# ioADuCM4050 register map
Registers are 16-bit, access not given, no defined reset value unless marked. A register's access mark holds for its fields unless they carry their own. Addresses are absolute; registers are grouped by the start of their names; [hi:lo] are bit positions; {n}, {i} and the like mark numbered series.

## UART1
0x40005400 UART1_RX
  [7:0] RBR
0x40005400 UART1_TX
  [7:0] THR
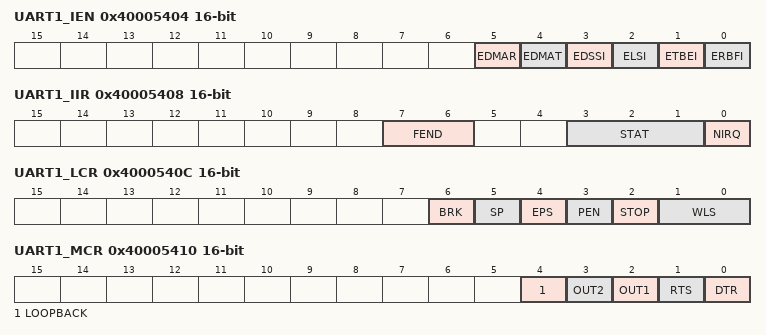
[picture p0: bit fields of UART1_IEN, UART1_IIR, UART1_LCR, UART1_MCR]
0x40005404 UART1_IEN
  [5] EDMAR, [4] EDMAT, [3] EDSSI, [2] ELSI, [1] ETBEI, [0] ERBFI
0x40005408 UART1_IIR
  [7:6] FEND, [3:1] STAT, [0] NIRQ
0x4000540C UART1_LCR
  [6] BRK, [5] SP, [4] EPS, [3] PEN, [2] STOP, [1:0] WLS
0x40005410 UART1_MCR
  [4] LOOPBACK, [3] OUT2, [2] OUT1, [1] RTS, [0] DTR
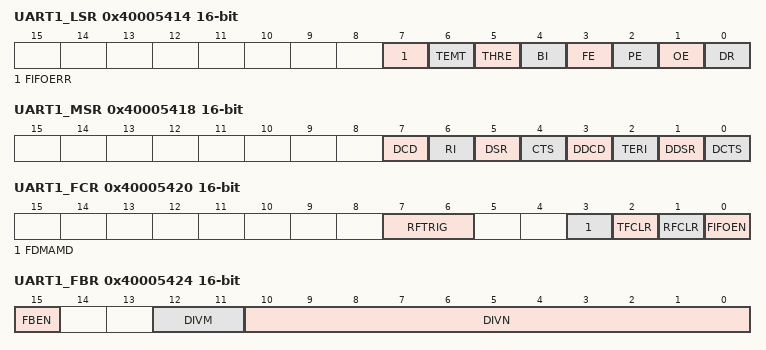
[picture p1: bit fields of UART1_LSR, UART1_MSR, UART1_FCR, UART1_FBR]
0x40005414 UART1_LSR
  [7] FIFOERR, [6] TEMT, [5] THRE, [4] BI, [3] FE, [2] PE, [1] OE, [0] DR
0x40005418 UART1_MSR
  [7] DCD, [6] RI, [5] DSR, [4] CTS, [3] DDCD, [2] TERI, [1] DDSR, [0] DCTS
0x4000541C UART1_SCR
  [7:0] SCR
0x40005420 UART1_FCR
  [7:6] RFTRIG, [3] FDMAMD, [2] TFCLR, [1] RFCLR, [0] FIFOEN
0x40005424 UART1_FBR
  [15] FBEN, [12:11] DIVM, [10:0] DIVN
0x40005428 UART1_DIV
0x4000542C UART1_LCR2
  [1:0] OSR
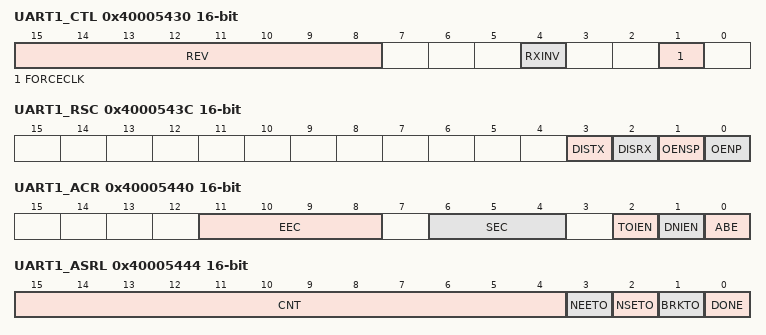
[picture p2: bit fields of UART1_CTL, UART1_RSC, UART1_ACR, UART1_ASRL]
0x40005430 UART1_CTL
  [15:8] REV, [4] RXINV, [1] FORCECLK
0x40005434 UART1_RFC
  [4:0] RFC
0x40005438 UART1_TFC
  [4:0] TFC
0x4000543C UART1_RSC
  [3] DISTX, [2] DISRX, [1] OENSP, [0] OENP
0x40005440 UART1_ACR
  [11:8] EEC, [6:4] SEC, [2] TOIEN, [1] DNIEN, [0] ABE
0x40005444 UART1_ASRL
  [15:4] CNT, [3] NEETO, [2] NSETO, [1] BRKTO, [0] DONE
0x40005448 UART1_ASRH
  [7:0] CNT

## BEEP0
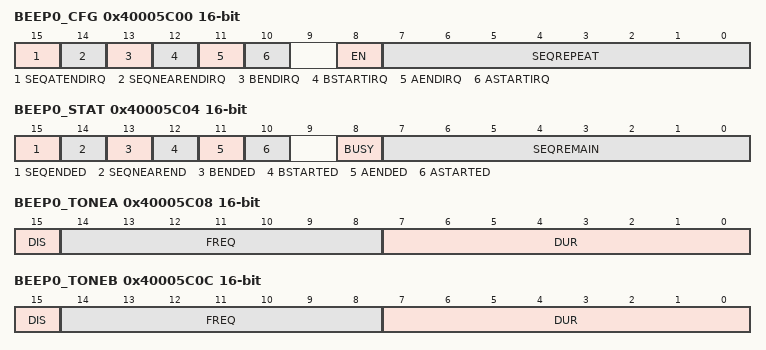
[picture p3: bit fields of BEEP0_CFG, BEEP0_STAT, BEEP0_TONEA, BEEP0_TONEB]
0x40005C00 BEEP0_CFG
  [15] SEQATENDIRQ, [14] SEQNEARENDIRQ, [13] BENDIRQ, [12] BSTARTIRQ, [11] AENDIRQ, [10] ASTARTIRQ, [8] EN, [7:0] SEQREPEAT
0x40005C04 BEEP0_STAT
  [15] SEQENDED, [14] SEQNEAREND, [13] BENDED, [12] BSTARTED, [11] AENDED, [10] ASTARTED, [8] BUSY, [7:0] SEQREMAIN
0x40005C08 BEEP0_TONEA
  [15] DIS, [14:8] FREQ, [7:0] DUR
0x40005C0C BEEP0_TONEB
  [15] DIS, [14:8] FREQ, [7:0] DUR

## ADC0
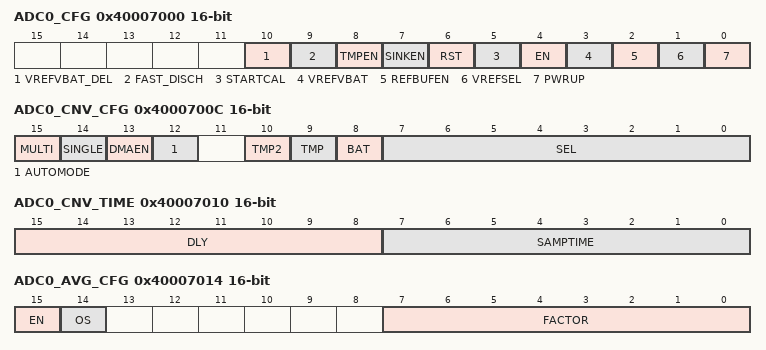
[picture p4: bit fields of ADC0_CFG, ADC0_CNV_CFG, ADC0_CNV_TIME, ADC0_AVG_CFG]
0x40007000 ADC0_CFG
  [10] VREFVBAT_DEL, [9] FAST_DISCH, [8] TMPEN, [7] SINKEN, [6] RST, [5] STARTCAL, [4] EN, [3] VREFVBAT, [2] REFBUFEN, [1] VREFSEL, [0] PWRUP
0x40007004 ADC0_PWRUP
  [10:0] WAIT
0x40007008 ADC0_CAL_WORD
  [6:0] VALUE
0x4000700C ADC0_CNV_CFG
  [15] MULTI, [14] SINGLE, [13] DMAEN, [12] AUTOMODE, [10] TMP2, [9] TMP, [8] BAT, [7:0] SEL
0x40007010 ADC0_CNV_TIME
  [15:8] DLY, [7:0] SAMPTIME
0x40007014 ADC0_AVG_CFG
  [15] EN, [14] OS, [7:0] FACTOR
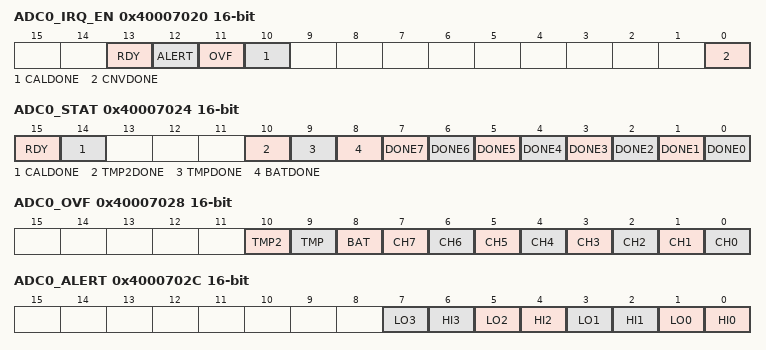
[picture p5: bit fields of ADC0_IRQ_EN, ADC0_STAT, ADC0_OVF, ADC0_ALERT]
0x40007020 ADC0_IRQ_EN
  [13] RDY, [12] ALERT, [11] OVF, [10] CALDONE, [0] CNVDONE
0x40007024 ADC0_STAT
  [15] RDY, [14] CALDONE, [10] TMP2DONE, [9] TMPDONE, [8] BATDONE, [n] DONE{n} (n=0..7)
0x40007028 ADC0_OVF
  [10] TMP2, [9] TMP, [8] BAT, [n] CH{n} (n=0..7)
0x4000702C ADC0_ALERT
  [2n+1] LO{n} (n=0..3), [2n] HI{n} (n=0..3)
{0x40007030+4i} ADC0_CH{i}_OUT (i=0..7)
0x40007050 ADC0_BAT_OUT
0x40007054 ADC0_TMP_OUT
0x40007058 ADC0_TMP2_OUT
0x4000705C ADC0_DMA_OUT
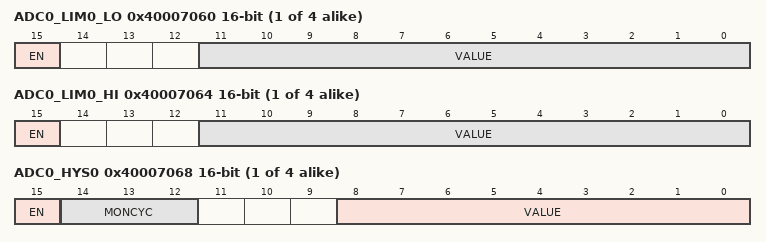
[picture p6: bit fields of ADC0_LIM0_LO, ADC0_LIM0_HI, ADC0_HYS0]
{0x40007060+0x10*i} ADC0_LIM{i}_LO (i=0..3)
  [15] EN, [11:0] VALUE
{0x40007064+0x10*i} ADC0_LIM{i}_HI (i=0..3)
  [15] EN, [11:0] VALUE
{0x40007068+0x10*i} ADC0_HYS{i} (i=0..3)
  [15] EN, [14:12] MONCYC, [8:0] VALUE
0x400070C0 ADC0_CFG1
  [0] RBUFLP

## DMA0
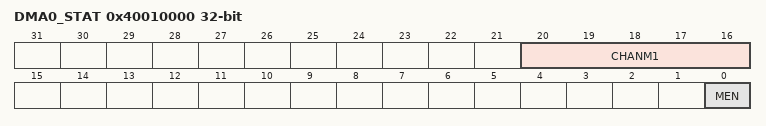
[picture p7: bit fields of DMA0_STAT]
0x40010000 DMA0_STAT 32-bit
  [20:16] CHANM1, [0] MEN
0x40010004 DMA0_CFG 32-bit
  [0] MEN
0x40010008 DMA0_PDBPTR 32-bit
0x4001000C DMA0_ADBPTR 32-bit
0x40010014 DMA0_SWREQ 32-bit
  [26:0] CHAN
0x40010020 DMA0_RMSK_SET 32-bit
  [26:0] CHAN
0x40010024 DMA0_RMSK_CLR 32-bit
  [26:0] CHAN
0x40010028 DMA0_EN_SET 32-bit
  [26:0] CHAN
0x4001002C DMA0_EN_CLR 32-bit
  [26:0] CHAN
0x40010030 DMA0_ALT_SET 32-bit
  [26:0] CHAN
0x40010034 DMA0_ALT_CLR 32-bit
  [26:0] CHAN
0x40010038 DMA0_PRI_SET 32-bit
  [26:0] CHAN
0x4001003C DMA0_PRI_CLR 32-bit
  [26:0] CHPRICLR
0x40010048 DMA0_ERRCHNL_CLR 32-bit
  [26:0] CHAN
0x4001004C DMA0_ERR_CLR 32-bit
  [26:0] CHAN
0x40010050 DMA0_INVALIDDESC_CLR 32-bit
  [26:0] CHAN
0x40010800 DMA0_BS_SET 32-bit
  [26:0] CHAN
0x40010804 DMA0_BS_CLR 32-bit
  [26:0] CHAN
0x40010810 DMA0_SRCADDR_SET 32-bit
  [26:0] CHAN
0x40010814 DMA0_SRCADDR_CLR 32-bit
  [26:0] CHAN
0x40010818 DMA0_DSTADDR_SET 32-bit
  [26:0] CHAN
0x4001081C DMA0_DSTADDR_CLR 32-bit
  [26:0] CHAN
0x40010FE0 DMA0_REVID 32-bit
  [7:0] VALUE
